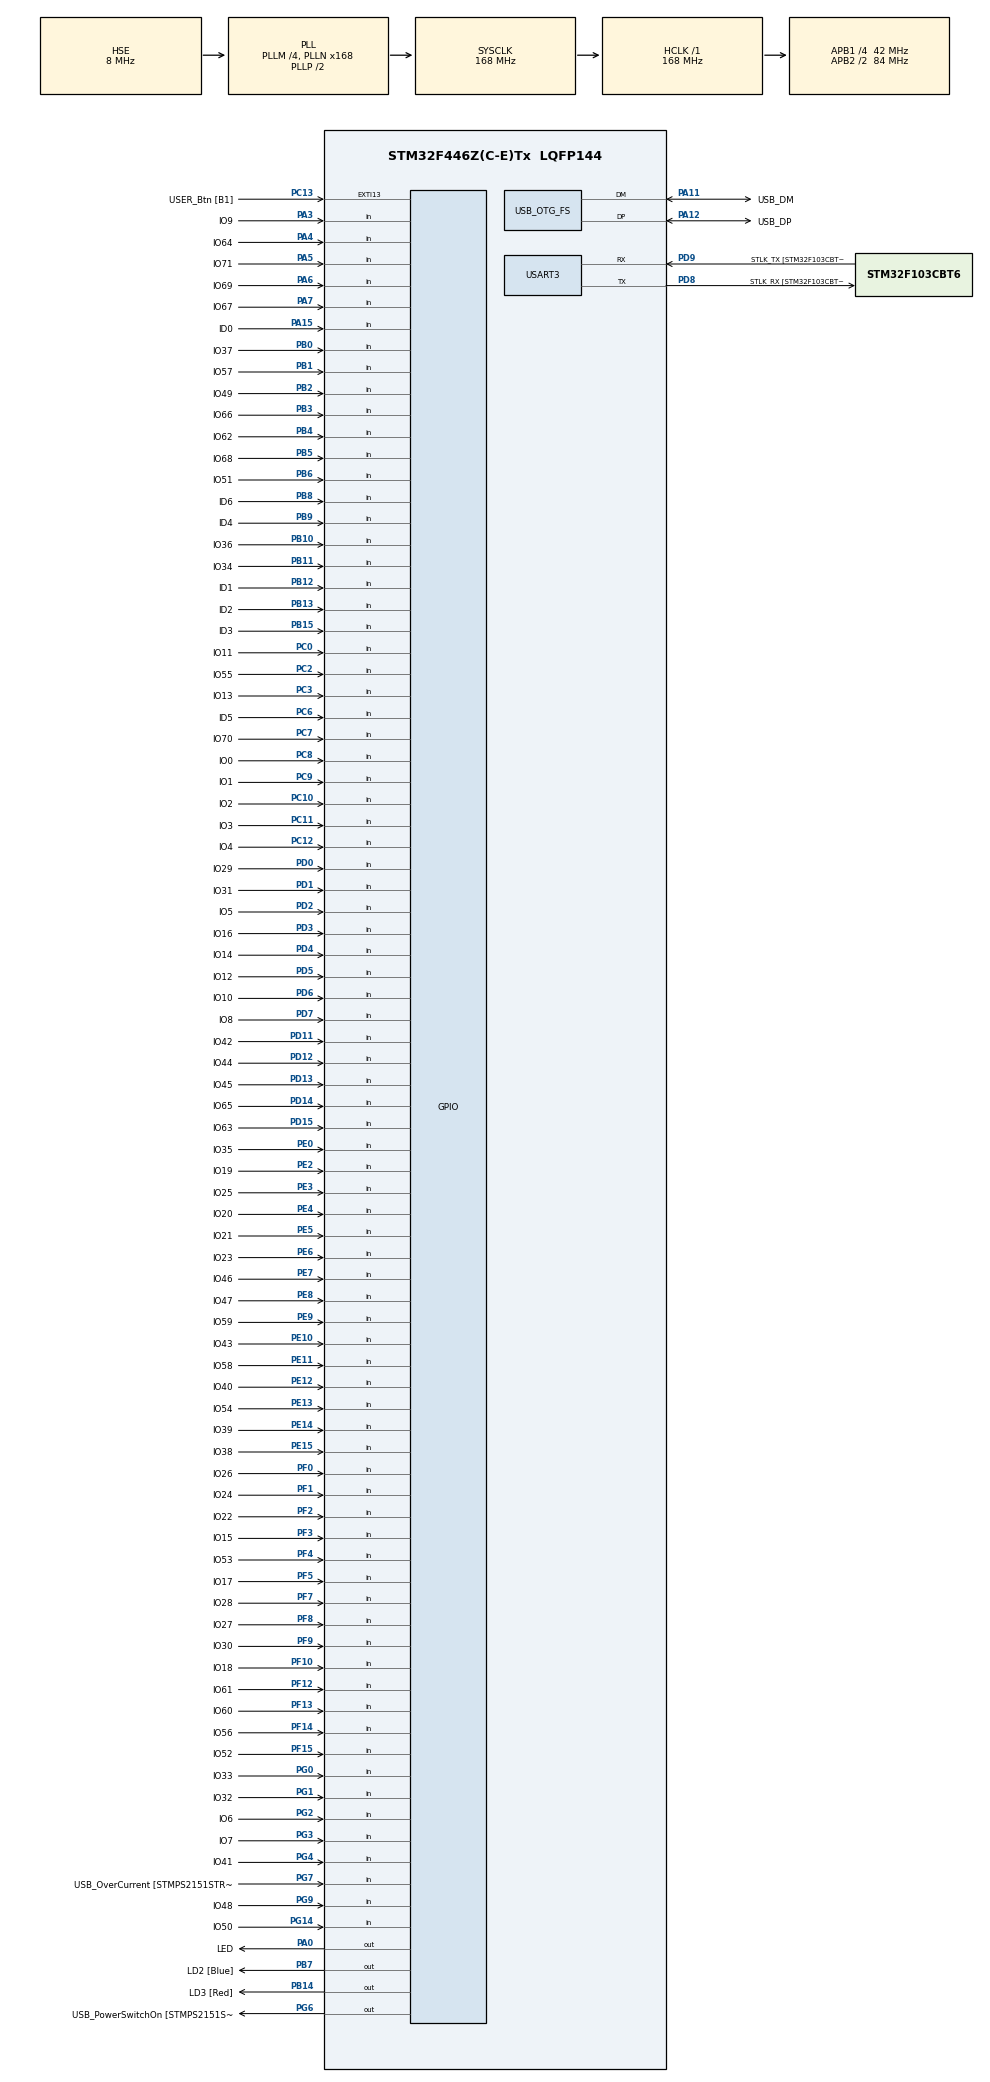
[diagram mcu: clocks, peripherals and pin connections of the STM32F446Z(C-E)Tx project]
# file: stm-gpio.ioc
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Mcu.Family=STM32F4
Mcu.Name=STM32F446Z(C-E)Tx
Mcu.Package=LQFP144
NVIC.OTG_FS_IRQn=true\:0\:0\:false\:false\:true\:false\:true\:true
NVIC.PriorityGroup=NVIC_PRIORITYGROUP_4
PA0-WKUP.GPIO_Label=LED
PA0-WKUP.Signal=GPIO_Output
PA10.GPIO_Label=USB_ID
PA10.Signal=USB_OTG_FS_ID
PA11.GPIO_Label=USB_DM
PA11.Mode=Device_Only
PA11.Signal=USB_OTG_FS_DM
PA12.GPIO_Label=USB_DP
PA12.Mode=Device_Only
PA12.Signal=USB_OTG_FS_DP
PA13.GPIO_Label=TMS
PA13.Mode=Serial_Wire
PA13.Signal=SYS_JTMS-SWDIO
PA14.GPIO_Label=TCK
PA14.Mode=Serial_Wire
PA14.Signal=SYS_JTCK-SWCLK
PA15.GPIO_Label=ID0
PA15.GPIO_PuPd=GPIO_PULLDOWN
PA15.Signal=GPIO_Input
PA3.GPIO_Label=IO9
PA3.GPIO_PuPd=GPIO_PULLDOWN
PA3.Signal=GPIO_Input
PA4.GPIO_Label=IO64
PA4.GPIO_PuPd=GPIO_PULLDOWN
PA4.Signal=GPIO_Input
PA5.GPIO_Label=IO71
PA5.GPIO_PuPd=GPIO_PULLDOWN
PA5.Signal=GPIO_Input
PA6.GPIO_Label=IO69
PA6.GPIO_PuPd=GPIO_PULLDOWN
PA6.Signal=GPIO_Input
PA7.GPIO_Label=IO67
PA7.GPIO_PuPd=GPIO_PULLDOWN
PA7.Signal=GPIO_Input
PA8.GPIO_Label=USB_SOF [TP1]
PA8.Signal=USB_OTG_FS_SOF
PA9.GPIO_Label=USB_VBUS
PA9.Signal=USB_OTG_FS_VBUS
PB0.GPIO_Label=IO37
PB0.GPIO_PuPd=GPIO_PULLDOWN
PB0.Signal=GPIO_Input
PB1.GPIO_Label=IO57
PB1.GPIO_PuPd=GPIO_PULLDOWN
PB1.Signal=GPIO_Input
PB10.GPIO_Label=IO36
PB10.GPIO_PuPd=GPIO_PULLDOWN
PB10.Signal=GPIO_Input
PB11.GPIO_Label=IO34
PB11.GPIO_PuPd=GPIO_PULLDOWN
PB11.Signal=GPIO_Input
PB12.GPIO_Label=ID1
PB12.GPIO_PuPd=GPIO_PULLDOWN
PB12.Signal=GPIO_Input
PB13.GPIO_Label=ID2
PB13.GPIO_PuPd=GPIO_PULLDOWN
PB13.Signal=GPIO_Input
PB14.GPIO_Label=LD3 [Red]
PB14.Signal=GPIO_Output
PB15.GPIO_Label=ID3
PB15.GPIO_PuPd=GPIO_PULLDOWN
PB15.Signal=GPIO_Input
PB2.GPIO_Label=IO49
PB2.GPIO_PuPd=GPIO_PULLDOWN
PB2.Signal=GPIO_Input
PB3.GPIO_Label=IO66
PB3.GPIO_PuPd=GPIO_PULLDOWN
PB3.Signal=GPIO_Input
PB4.GPIO_Label=IO62
PB4.GPIO_PuPd=GPIO_PULLDOWN
PB4.Signal=GPIO_Input
PB5.GPIO_Label=IO68
PB5.GPIO_PuPd=GPIO_PULLDOWN
PB5.Signal=GPIO_Input
PB6.GPIO_Label=IO51
PB6.GPIO_PuPd=GPIO_PULLDOWN
PB6.Signal=GPIO_Input
PB7.GPIO_Label=LD2 [Blue]
PB7.Signal=GPIO_Output
PB8.GPIO_Label=ID6
PB8.GPIO_PuPd=GPIO_PULLDOWN
PB8.Signal=GPIO_Input
PB9.GPIO_Label=ID4
PB9.GPIO_PuPd=GPIO_PULLDOWN
PB9.Signal=GPIO_Input
PC0.GPIO_Label=IO11
PC0.GPIO_PuPd=GPIO_PULLDOWN
PC0.Signal=GPIO_Input
PC10.GPIO_Label=IO2
PC10.GPIO_PuPd=GPIO_PULLDOWN
PC10.Signal=GPIO_Input
PC11.GPIO_Label=IO3
PC11.GPIO_PuPd=GPIO_PULLDOWN
PC11.Signal=GPIO_Input
PC12.GPIO_Label=IO4
PC12.GPIO_PuPd=GPIO_PULLDOWN
PC12.Signal=GPIO_Input
PC13.GPIO_Label=USER_Btn [B1]
PC13.Signal=GPXTI13
PC14-OSC32_IN.Mode=LSE-External-Oscillator
PC14-OSC32_IN.Signal=RCC_OSC32_IN
PC15-OSC32_OUT.Mode=LSE-External-Oscillator
PC15-OSC32_OUT.Signal=RCC_OSC32_OUT
PC2.GPIO_Label=IO55
PC2.GPIO_PuPd=GPIO_PULLDOWN
PC2.Signal=GPIO_Input
PC3.GPIO_Label=IO13
PC3.GPIO_PuPd=GPIO_PULLDOWN
PC3.Signal=GPIO_Input
PC6.GPIO_Label=ID5
PC6.GPIO_PuPd=GPIO_PULLDOWN
PC6.Signal=GPIO_Input
PC7.GPIO_Label=IO70
PC7.GPIO_PuPd=GPIO_PULLDOWN
PC7.Signal=GPIO_Input
PC8.GPIO_Label=IO0
PC8.GPIO_PuPd=GPIO_PULLDOWN
PC8.Signal=GPIO_Input
PC9.GPIO_Label=IO1
PC9.GPIO_PuPd=GPIO_PULLDOWN
PC9.Signal=GPIO_Input
PD0.GPIO_Label=IO29
PD0.GPIO_PuPd=GPIO_PULLDOWN
PD0.Signal=GPIO_Input
PD1.GPIO_Label=IO31
PD1.GPIO_PuPd=GPIO_PULLDOWN
PD1.Signal=GPIO_Input
PD11.GPIO_Label=IO42
PD11.GPIO_PuPd=GPIO_PULLDOWN
PD11.Signal=GPIO_Input
PD12.GPIO_Label=IO44
PD12.GPIO_PuPd=GPIO_PULLDOWN
PD12.Signal=GPIO_Input
PD13.GPIO_Label=IO45
PD13.GPIO_PuPd=GPIO_PULLDOWN
PD13.Signal=GPIO_Input
PD14.GPIO_Label=IO65
PD14.GPIO_PuPd=GPIO_PULLDOWN
PD14.Signal=GPIO_Input
PD15.GPIO_Label=IO63
PD15.GPIO_PuPd=GPIO_PULLDOWN
PD15.Signal=GPIO_Input
PD2.GPIO_Label=IO5
PD2.GPIO_PuPd=GPIO_PULLDOWN
PD2.Signal=GPIO_Input
PD3.GPIO_Label=IO16
PD3.GPIO_PuPd=GPIO_PULLDOWN
PD3.Signal=GPIO_Input
PD4.GPIO_Label=IO14
PD4.GPIO_PuPd=GPIO_PULLDOWN
PD4.Signal=GPIO_Input
PD5.GPIO_Label=IO12
PD5.GPIO_PuPd=GPIO_PULLDOWN
PD5.Signal=GPIO_Input
PD6.GPIO_Label=IO10
PD6.GPIO_PuPd=GPIO_PULLDOWN
PD6.Signal=GPIO_Input
PD7.GPIO_Label=IO8
PD7.GPIO_PuPd=GPIO_PULLDOWN
PD7.Signal=GPIO_Input
PD8.GPIO_Label=STLK_RX [STM32F103CBT6_PA3]
PD8.Mode=Asynchronous
PD8.Signal=USART3_TX
PD9.GPIO_Label=STLK_TX [STM32F103CBT6_PA2]
PD9.Mode=Asynchronous
PD9.Signal=USART3_RX
PE0.GPIO_Label=IO35
PE0.GPIO_PuPd=GPIO_PULLDOWN
PE0.Signal=GPIO_Input
PE10.GPIO_Label=IO43
PE10.GPIO_PuPd=GPIO_PULLDOWN
PE10.Signal=GPIO_Input
PE11.GPIO_Label=IO58
PE11.GPIO_PuPd=GPIO_PULLDOWN
PE11.Signal=GPIO_Input
PE12.GPIO_Label=IO40
PE12.GPIO_PuPd=GPIO_PULLDOWN
PE12.Signal=GPIO_Input
PE13.GPIO_Label=IO54
PE13.GPIO_PuPd=GPIO_PULLDOWN
PE13.Signal=GPIO_Input
PE14.GPIO_Label=IO39
PE14.GPIO_PuPd=GPIO_PULLDOWN
PE14.Signal=GPIO_Input
PE15.GPIO_Label=IO38
PE15.GPIO_PuPd=GPIO_PULLDOWN
PE15.Signal=GPIO_Input
PE2.GPIO_Label=IO19
PE2.GPIO_PuPd=GPIO_PULLDOWN
PE2.Signal=GPIO_Input
PE3.GPIO_Label=IO25
PE3.GPIO_PuPd=GPIO_PULLDOWN
PE3.Signal=GPIO_Input
PE4.GPIO_Label=IO20
PE4.GPIO_PuPd=GPIO_PULLDOWN
PE4.Signal=GPIO_Input
PE5.GPIO_Label=IO21
PE5.GPIO_PuPd=GPIO_PULLDOWN
PE5.Signal=GPIO_Input
PE6.GPIO_Label=IO23
PE6.GPIO_PuPd=GPIO_PULLDOWN
PE6.Signal=GPIO_Input
PE7.GPIO_Label=IO46
PE7.GPIO_PuPd=GPIO_PULLDOWN
PE7.Signal=GPIO_Input
PE8.GPIO_Label=IO47
PE8.GPIO_PuPd=GPIO_PULLDOWN
PE8.Signal=GPIO_Input
PE9.GPIO_Label=IO59
PE9.GPIO_PuPd=GPIO_PULLDOWN
PE9.Signal=GPIO_Input
PF0.GPIO_Label=IO26
PF0.GPIO_PuPd=GPIO_PULLDOWN
PF0.Signal=GPIO_Input
PF1.GPIO_Label=IO24
PF1.GPIO_PuPd=GPIO_PULLDOWN
PF1.Signal=GPIO_Input
PF10.GPIO_Label=IO18
PF10.GPIO_PuPd=GPIO_PULLDOWN
PF10.Signal=GPIO_Input
PF12.GPIO_Label=IO61
PF12.GPIO_PuPd=GPIO_PULLDOWN
PF12.Signal=GPIO_Input
PF13.GPIO_Label=IO60
PF13.GPIO_PuPd=GPIO_PULLDOWN
PF13.Signal=GPIO_Input
PF14.GPIO_Label=IO56
PF14.GPIO_PuPd=GPIO_PULLDOWN
PF14.Signal=GPIO_Input
PF15.GPIO_Label=IO52
PF15.GPIO_PuPd=GPIO_PULLDOWN
PF15.Signal=GPIO_Input
PF2.GPIO_Label=IO22
PF2.GPIO_PuPd=GPIO_PULLDOWN
PF2.Signal=GPIO_Input
PF3.GPIO_Label=IO15
PF3.GPIO_PuPd=GPIO_PULLDOWN
PF3.Signal=GPIO_Input
PF4.GPIO_Label=IO53
PF4.GPIO_PuPd=GPIO_PULLDOWN
PF4.Signal=GPIO_Input
PF5.GPIO_Label=IO17
PF5.GPIO_PuPd=GPIO_PULLDOWN
PF5.Signal=GPIO_Input
PF7.GPIO_Label=IO28
PF7.GPIO_PuPd=GPIO_PULLDOWN
PF7.Signal=GPIO_Input
PF8.GPIO_Label=IO27
PF8.GPIO_PuPd=GPIO_PULLDOWN
PF8.Signal=GPIO_Input
PF9.GPIO_Label=IO30
PF9.GPIO_PuPd=GPIO_PULLDOWN
PF9.Signal=GPIO_Input
PG0.GPIO_Label=IO33
PG0.GPIO_PuPd=GPIO_PULLDOWN
PG0.Signal=GPIO_Input
PG1.GPIO_Label=IO32
PG1.GPIO_PuPd=GPIO_PULLDOWN
PG1.Signal=GPIO_Input
PG14.GPIO_Label=IO50
PG14.GPIO_PuPd=GPIO_PULLDOWN
PG14.Signal=GPIO_Input
PG2.GPIO_Label=IO6
PG2.GPIO_PuPd=GPIO_PULLDOWN
PG2.Signal=GPIO_Input
PG3.GPIO_Label=IO7
PG3.GPIO_PuPd=GPIO_PULLDOWN
PG3.Signal=GPIO_Input
PG4.GPIO_Label=IO41
PG4.GPIO_PuPd=GPIO_PULLDOWN
PG4.Signal=GPIO_Input
PG6.GPIO_Label=USB_PowerSwitchOn [STMPS2151STR_EN]
PG6.Signal=GPIO_Output
PG7.GPIO_Label=USB_OverCurrent [STMPS2151STR_FAULT]
PG7.Signal=GPIO_Input
PG9.GPIO_Label=IO48
PG9.GPIO_PuPd=GPIO_PULLDOWN
PG9.Signal=GPIO_Input
PH0-OSC_IN.GPIO_Label=MCO [STM32F103CBT6_PA8]
PH0-OSC_IN.Mode=HSE-External-Clock-Source
PH0-OSC_IN.Signal=RCC_OSC_IN
PH1-OSC_OUT.Mode=HSE-External-Clock-Source
PH1-OSC_OUT.Signal=RCC_OSC_OUT
ProjectManager.HeapSize=0x200
ProjectManager.StackSize=0x400
ProjectManager.TargetToolchain=CMake
RCC.48MHZClocksFreq_Value=24000000
RCC.AHBFreq_Value=168000000
RCC.APB1CLKDivider=RCC_HCLK_DIV4
RCC.APB1Freq_Value=42000000
RCC.APB1TimFreq_Value=84000000
RCC.APB2CLKDivider=RCC_HCLK_DIV2
RCC.APB2Freq_Value=84000000
RCC.APB2TimFreq_Value=168000000
RCC.CortexFreq_Value=168000000
RCC.HCLKFreq_Value=168000000
RCC.HSE_VALUE=8000000
RCC.HSI_VALUE=16000000
RCC.PLLM=4
RCC.PLLMUL=RCC_PLL_MUL9
RCC.PLLN=168
RCC.PLLQ=7
RCC.PRESCALERUSB=RCC_USBCLKSOURCE_PLL_DIV1_5
RCC.SYSCLKFreq_VALUE=168000000
RCC.SYSCLKSource=RCC_SYSCLKSOURCE_PLLCLK
RCC.SYSCLKSourceVirtual=RCC_SYSCLKSOURCE_PLLCLK
RCC.USBFreq_Value=48000000
RCC.VCOOutputFreq_Value=336000000
USART3.VirtualMode=VM_ASYNC
USB_DEVICE.CLASS_NAME_FS=CDC
USB_DEVICE.MANUFACTURER_STRING-CDC_FS=TurnAroundFactor
USB_DEVICE.PID_CDC_FS=49239
USB_DEVICE.PRODUCT_STRING_CDC_FS=Netlist Generator
USB_DEVICE.VID-CDC_FS=29033
USB_DEVICE.VirtualMode-CDC_FS=Cdc
USB_DEVICE.VirtualModeFS=Cdc_FS
USB_OTG_FS.VirtualMode=Device_Only
VP_USB_DEVICE_VS_USB_DEVICE_CDC_FS.Mode=CDC_FS
board=NUCLEO-F446ZE

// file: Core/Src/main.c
/* USER CODE BEGIN Header */
/**
 ******************************************************************************
 * @file           : main.c
 * @brief          : Main program body
 ******************************************************************************
 * @attention
 *
 * Copyright (c) 2025 STMicroelectronics.
 * All rights reserved.
 *
 * This software is licensed under terms that can be found in the LICENSE file
 * in the root directory of this software component.
 * If no LICENSE file comes with this software, it is provided AS-IS.
 *
 ******************************************************************************
 */
/* USER CODE END Header */
#include "main.h"
#include "usb_device.h"

/* USER CODE BEGIN Includes */
#include "task_main.h"

/* USER CODE END Includes */

UART_HandleTypeDef huart3;

void SystemClock_Config(void);
static void MX_GPIO_Init(void);
static void MX_USART3_UART_Init(void);

int main(void)
{

  /* MCU Configuration--------------------------------------------------------*/

  /* Reset of all peripherals, Initializes the Flash interface and the Systick. */
  HAL_Init();

  /* Configure the system clock */
  SystemClock_Config();

  /* Initialize all configured peripherals */
  MX_GPIO_Init();
  MX_USART3_UART_Init();
  MX_USB_DEVICE_Init();
  /* USER CODE BEGIN 2 */
  Debug("Hello USB!\r\n");
  Main_Setup();

  /* USER CODE END 2 */

  /* Infinite loop */
  /* USER CODE BEGIN WHILE */

  while (1)
  {
    Main_Loop();

    /* USER CODE END WHILE */

  }
}

void SystemClock_Config(void)
{
  RCC_OscInitTypeDef RCC_OscInitStruct = {0};
  RCC_ClkInitTypeDef RCC_ClkInitStruct = {0};

  /** Configure the main internal regulator output voltage
   */
  __HAL_RCC_PWR_CLK_ENABLE();
  __HAL_PWR_VOLTAGESCALING_CONFIG(PWR_REGULATOR_VOLTAGE_SCALE1);

  /** Initializes the RCC Oscillators according to the specified parameters
   * in the RCC_OscInitTypeDef structure.
   */
  RCC_OscInitStruct.OscillatorType = RCC_OSCILLATORTYPE_HSE;
  RCC_OscInitStruct.HSEState = RCC_HSE_BYPASS;
  RCC_OscInitStruct.PLL.PLLState = RCC_PLL_ON;
  RCC_OscInitStruct.PLL.PLLSource = RCC_PLLSOURCE_HSE;
  RCC_OscInitStruct.PLL.PLLM = 4;
  RCC_OscInitStruct.PLL.PLLN = 168;
  RCC_OscInitStruct.PLL.PLLP = RCC_PLLP_DIV2;
  RCC_OscInitStruct.PLL.PLLQ = 7;
  RCC_OscInitStruct.PLL.PLLR = 2;
  if (HAL_RCC_OscConfig(&RCC_OscInitStruct) != HAL_OK)
  {
    Error_Handler();
  }

  /** Initializes the CPU, AHB and APB buses clocks
   */
  RCC_ClkInitStruct.ClockType = RCC_CLOCKTYPE_HCLK | RCC_CLOCKTYPE_SYSCLK | RCC_CLOCKTYPE_PCLK1 | RCC_CLOCKTYPE_PCLK2;
  RCC_ClkInitStruct.SYSCLKSource = RCC_SYSCLKSOURCE_PLLCLK;
  RCC_ClkInitStruct.AHBCLKDivider = RCC_SYSCLK_DIV1;
  RCC_ClkInitStruct.APB1CLKDivider = RCC_HCLK_DIV4;
  RCC_ClkInitStruct.APB2CLKDivider = RCC_HCLK_DIV2;

  if (HAL_RCC_ClockConfig(&RCC_ClkInitStruct, FLASH_LATENCY_5) != HAL_OK)
  {
    Error_Handler();
  }
}

static void MX_USART3_UART_Init(void)
{

  huart3.Instance = USART3;
  huart3.Init.BaudRate = 115200;
  huart3.Init.WordLength = UART_WORDLENGTH_8B;
  huart3.Init.StopBits = UART_STOPBITS_1;
  huart3.Init.Parity = UART_PARITY_NONE;
  huart3.Init.Mode = UART_MODE_TX_RX;
  huart3.Init.HwFlowCtl = UART_HWCONTROL_NONE;
  huart3.Init.OverSampling = UART_OVERSAMPLING_16;
  if (HAL_UART_Init(&huart3) != HAL_OK)
  {
    Error_Handler();
  }
}

static void MX_GPIO_Init(void)
{
  GPIO_InitTypeDef GPIO_InitStruct = {0};

  /* GPIO Ports Clock Enable */
  __HAL_RCC_GPIOE_CLK_ENABLE();
  __HAL_RCC_GPIOC_CLK_ENABLE();
  __HAL_RCC_GPIOF_CLK_ENABLE();
  __HAL_RCC_GPIOH_CLK_ENABLE();
  __HAL_RCC_GPIOA_CLK_ENABLE();
  __HAL_RCC_GPIOB_CLK_ENABLE();
  __HAL_RCC_GPIOG_CLK_ENABLE();
  __HAL_RCC_GPIOD_CLK_ENABLE();

  /*Configure GPIO pin Output Level */
  HAL_GPIO_WritePin(LED_GPIO_Port, LED_Pin, GPIO_PIN_RESET);

  /*Configure GPIO pin Output Level */
  HAL_GPIO_WritePin(GPIOB, LD3_Pin | LD2_Pin, GPIO_PIN_RESET);

  /*Configure GPIO pin Output Level */
  HAL_GPIO_WritePin(USB_PowerSwitchOn_GPIO_Port, USB_PowerSwitchOn_Pin, GPIO_PIN_RESET);

  /*Configure GPIO pins : IO19_Pin IO25_Pin IO20_Pin IO21_Pin
                           IO23_Pin IO46_Pin IO47_Pin IO59_Pin
                           IO43_Pin IO58_Pin IO40_Pin IO54_Pin
                           IO39_Pin IO38_Pin IO35_Pin */
  GPIO_InitStruct.Pin = IO19_Pin | IO25_Pin | IO20_Pin | IO21_Pin | IO23_Pin | IO46_Pin | IO47_Pin | IO59_Pin | IO43_Pin | IO58_Pin | IO40_Pin | IO54_Pin | IO39_Pin | IO38_Pin | IO35_Pin;
  GPIO_InitStruct.Mode = GPIO_MODE_INPUT;
  GPIO_InitStruct.Pull = GPIO_PULLDOWN;
  HAL_GPIO_Init(GPIOE, &GPIO_InitStruct);

  /*Configure GPIO pin : USER_Btn_Pin */
  GPIO_InitStruct.Pin = USER_Btn_Pin;
  GPIO_InitStruct.Mode = GPIO_MODE_IT_RISING;
  GPIO_InitStruct.Pull = GPIO_NOPULL;
  HAL_GPIO_Init(USER_Btn_GPIO_Port, &GPIO_InitStruct);

  /*Configure GPIO pins : IO26_Pin IO24_Pin IO22_Pin IO15_Pin
                           IO53_Pin IO17_Pin IO28_Pin IO27_Pin
                           IO30_Pin IO18_Pin IO61_Pin IO60_Pin
                           IO56_Pin IO52_Pin */
  GPIO_InitStruct.Pin = IO26_Pin | IO24_Pin | IO22_Pin | IO15_Pin | IO53_Pin | IO17_Pin | IO28_Pin | IO27_Pin | IO30_Pin | IO18_Pin | IO61_Pin | IO60_Pin | IO56_Pin | IO52_Pin;
  GPIO_InitStruct.Mode = GPIO_MODE_INPUT;
  GPIO_InitStruct.Pull = GPIO_PULLDOWN;
  HAL_GPIO_Init(GPIOF, &GPIO_InitStruct);

  /*Configure GPIO pins : IO11_Pin IO55_Pin IO13_Pin ID5_Pin
                           IO70_Pin IO0_Pin IO1_Pin IO2_Pin
                           IO3_Pin IO4_Pin */
  GPIO_InitStruct.Pin = IO11_Pin | IO55_Pin | IO13_Pin | ID5_Pin | IO70_Pin | IO0_Pin | IO1_Pin | IO2_Pin | IO3_Pin | IO4_Pin;
  GPIO_InitStruct.Mode = GPIO_MODE_INPUT;
  GPIO_InitStruct.Pull = GPIO_PULLDOWN;
  HAL_GPIO_Init(GPIOC, &GPIO_InitStruct);

  /*Configure GPIO pin : LED_Pin */
  GPIO_InitStruct.Pin = LED_Pin;
  GPIO_InitStruct.Mode = GPIO_MODE_OUTPUT_PP;
  GPIO_InitStruct.Pull = GPIO_NOPULL;
  GPIO_InitStruct.Speed = GPIO_SPEED_FREQ_LOW;
  HAL_GPIO_Init(LED_GPIO_Port, &GPIO_InitStruct);

  /*Configure GPIO pins : IO9_Pin IO64_Pin IO71_Pin IO69_Pin
                           IO67_Pin ID0_Pin */
  GPIO_InitStruct.Pin = IO9_Pin | IO64_Pin | IO71_Pin | IO69_Pin | IO67_Pin | ID0_Pin;
  GPIO_InitStruct.Mode = GPIO_MODE_INPUT;
  GPIO_InitStruct.Pull = GPIO_PULLDOWN;
  HAL_GPIO_Init(GPIOA, &GPIO_InitStruct);

  /*Configure GPIO pins : IO37_Pin IO57_Pin IO49_Pin IO36_Pin
                           IO34_Pin ID1_Pin ID2_Pin ID3_Pin
                           IO66_Pin IO62_Pin IO68_Pin IO51_Pin
                           ID6_Pin ID4_Pin */
  GPIO_InitStruct.Pin = IO37_Pin | IO57_Pin | IO49_Pin | IO36_Pin | IO34_Pin | ID1_Pin | ID2_Pin | ID3_Pin | IO66_Pin | IO62_Pin | IO68_Pin | IO51_Pin | ID6_Pin | ID4_Pin;
  GPIO_InitStruct.Mode = GPIO_MODE_INPUT;
  GPIO_InitStruct.Pull = GPIO_PULLDOWN;
  HAL_GPIO_Init(GPIOB, &GPIO_InitStruct);

  /*Configure GPIO pins : IO33_Pin IO32_Pin IO6_Pin IO7_Pin
                           IO41_Pin IO48_Pin IO50_Pin */
  GPIO_InitStruct.Pin = IO33_Pin | IO32_Pin | IO6_Pin | IO7_Pin | IO41_Pin | IO48_Pin | IO50_Pin;
  GPIO_InitStruct.Mode = GPIO_MODE_INPUT;
  GPIO_InitStruct.Pull = GPIO_PULLDOWN;
  HAL_GPIO_Init(GPIOG, &GPIO_InitStruct);

  /*Configure GPIO pins : LD3_Pin LD2_Pin */
  GPIO_InitStruct.Pin = LD3_Pin | LD2_Pin;
  GPIO_InitStruct.Mode = GPIO_MODE_OUTPUT_PP;
  GPIO_InitStruct.Pull = GPIO_NOPULL;
  GPIO_InitStruct.Speed = GPIO_SPEED_FREQ_LOW;
  HAL_GPIO_Init(GPIOB, &GPIO_InitStruct);

  /*Configure GPIO pins : IO42_Pin IO44_Pin IO45_Pin IO65_Pin
                           IO63_Pin IO29_Pin IO31_Pin IO5_Pin
                           IO16_Pin IO14_Pin IO12_Pin IO10_Pin
                           IO8_Pin */
  GPIO_InitStruct.Pin = IO42_Pin | IO44_Pin | IO45_Pin | IO65_Pin | IO63_Pin | IO29_Pin | IO31_Pin | IO5_Pin | IO16_Pin | IO14_Pin | IO12_Pin | IO10_Pin | IO8_Pin;
  GPIO_InitStruct.Mode = GPIO_MODE_INPUT;
  GPIO_InitStruct.Pull = GPIO_PULLDOWN;
  HAL_GPIO_Init(GPIOD, &GPIO_InitStruct);

  /*Configure GPIO pin : USB_PowerSwitchOn_Pin */
  GPIO_InitStruct.Pin = USB_PowerSwitchOn_Pin;
  GPIO_InitStruct.Mode = GPIO_MODE_OUTPUT_PP;
  GPIO_InitStruct.Pull = GPIO_NOPULL;
  GPIO_InitStruct.Speed = GPIO_SPEED_FREQ_LOW;
  HAL_GPIO_Init(USB_PowerSwitchOn_GPIO_Port, &GPIO_InitStruct);

  /*Configure GPIO pin : USB_OverCurrent_Pin */
  GPIO_InitStruct.Pin = USB_OverCurrent_Pin;
  GPIO_InitStruct.Mode = GPIO_MODE_INPUT;
  GPIO_InitStruct.Pull = GPIO_NOPULL;
  HAL_GPIO_Init(USB_OverCurrent_GPIO_Port, &GPIO_InitStruct);

}

void Error_Handler(void)
{
  __disable_irq();
  while (1)
  {
  }
}
